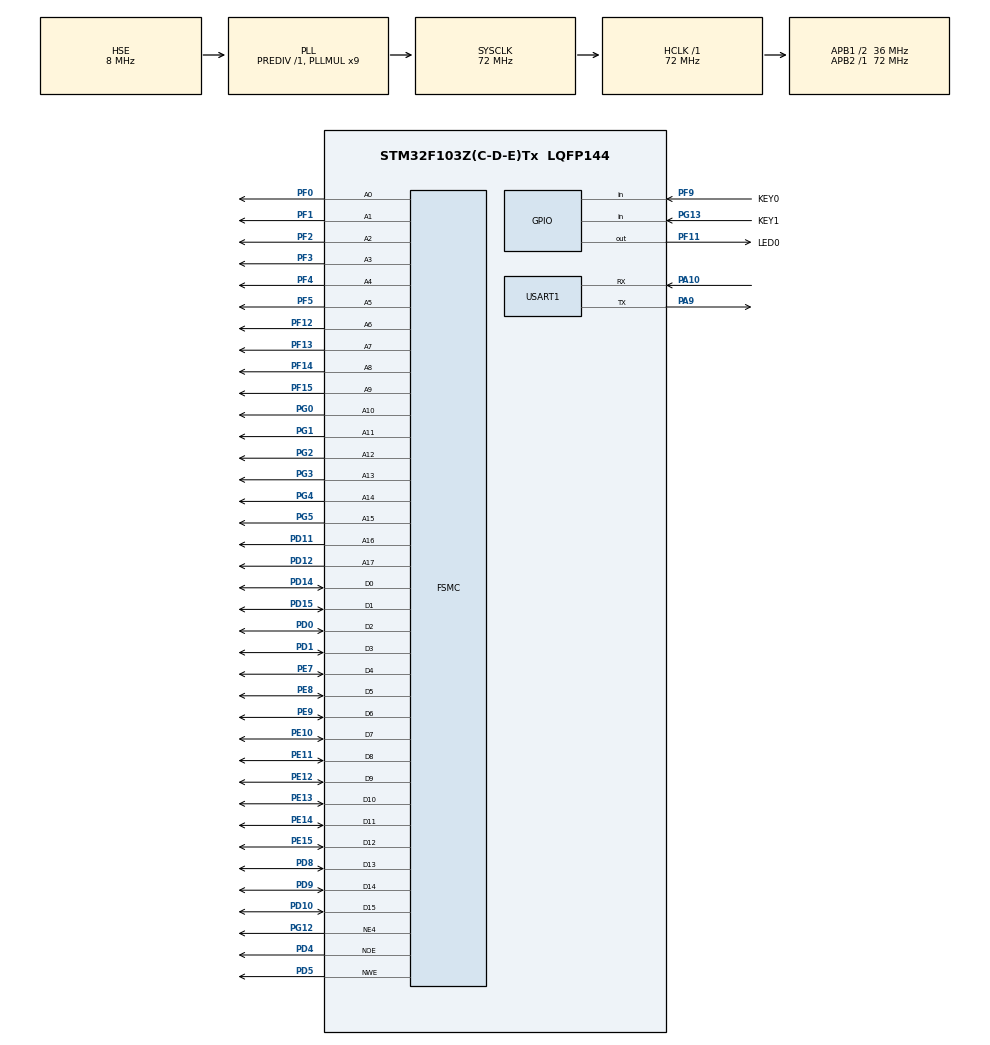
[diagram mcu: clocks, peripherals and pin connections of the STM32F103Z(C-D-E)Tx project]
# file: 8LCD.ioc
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FSMC.AddressSetupTime1=0
FSMC.DataSetupTime1=3
FSMC.WriteOperation1=FSMC_WRITE_OPERATION_ENABLE
Mcu.Family=STM32F1
Mcu.Name=STM32F103Z(C-D-E)Tx
Mcu.Package=LQFP144
NVIC.PriorityGroup=NVIC_PRIORITYGROUP_4
OSC_IN.Mode=HSE-External-Oscillator
OSC_IN.Signal=RCC_OSC_IN
OSC_OUT.Mode=HSE-External-Oscillator
OSC_OUT.Signal=RCC_OSC_OUT
PA10.Mode=Asynchronous
PA10.Signal=USART1_RX
PA13.Mode=Serial_Wire
PA13.Signal=SYS_JTMS-SWDIO
PA14.Mode=Serial_Wire
PA14.Signal=SYS_JTCK-SWCLK
PA9.Mode=Asynchronous
PA9.Signal=USART1_TX
PC14-OSC32_IN.Mode=LSE-External-Oscillator
PC14-OSC32_IN.Signal=RCC_OSC32_IN
PC15-OSC32_OUT.Mode=LSE-External-Oscillator
PC15-OSC32_OUT.Signal=RCC_OSC32_OUT
PD0.Signal=FSMC_D2_DA2
PD1.Signal=FSMC_D3_DA3
PD10.Signal=FSMC_D15_DA15
PD11.Signal=FSMC_A16_CLE
PD12.Signal=FSMC_A17_ALE
PD14.Signal=FSMC_D0_DA0
PD15.Signal=FSMC_D1_DA1
PD4.Signal=FSMC_NOE
PD5.Signal=FSMC_NWE
PD8.Signal=FSMC_D13_DA13
PD9.Signal=FSMC_D14_DA14
PE10.Signal=FSMC_D7_DA7
PE11.Signal=FSMC_D8_DA8
PE12.Signal=FSMC_D9_DA9
PE13.Signal=FSMC_D10_DA10
PE14.Signal=FSMC_D11_DA11
PE15.Signal=FSMC_D12_DA12
PE7.Signal=FSMC_D4_DA4
PE8.Signal=FSMC_D5_DA5
PE9.Signal=FSMC_D6_DA6
PF0.Signal=FSMC_A0
PF1.Signal=FSMC_A1
PF11.GPIO_Label=LED0
PF11.Signal=GPIO_Output
PF12.Signal=FSMC_A6
PF13.Signal=FSMC_A7
PF14.Signal=FSMC_A8
PF15.Signal=FSMC_A9
PF2.Signal=FSMC_A2
PF3.Signal=FSMC_A3
PF4.Signal=FSMC_A4
PF5.Signal=FSMC_A5
PF9.GPIO_Label=KEY0
PF9.GPIO_PuPd=GPIO_PULLUP
PF9.Signal=GPIO_Input
PG0.Signal=FSMC_A10
PG1.Signal=FSMC_A11
PG12.Mode=NorPsramChipSelect4_1
PG12.Signal=FSMC_NE4
PG13.GPIO_Label=KEY1
PG13.GPIO_PuPd=GPIO_PULLUP
PG13.Signal=GPIO_Input
PG2.Signal=FSMC_A12
PG3.Signal=FSMC_A13
PG4.Signal=FSMC_A14
PG5.Signal=FSMC_A15
ProjectManager.HeapSize=0x200
ProjectManager.StackSize=0x400
ProjectManager.TargetToolchain=MDK-ARM V5.27
RCC.AHBFreq_Value=72000000
RCC.APB1CLKDivider=RCC_HCLK_DIV2
RCC.APB1Freq_Value=36000000
RCC.APB1TimFreq_Value=72000000
RCC.APB2Freq_Value=72000000
RCC.APB2TimFreq_Value=72000000
RCC.HCLKFreq_Value=72000000
RCC.PLLMUL=RCC_PLL_MUL9
RCC.PLLSourceVirtual=RCC_PLLSOURCE_HSE
RCC.SYSCLKFreq_VALUE=72000000
RCC.SYSCLKSource=RCC_SYSCLKSOURCE_PLLCLK
RCC.USBFreq_Value=72000000
SH.FSMC_A0.0=FSMC_A0,18b-a1
SH.FSMC_A1.0=FSMC_A1,18b-a1
SH.FSMC_A10.0=FSMC_A10,18b-a1
SH.FSMC_A11.0=FSMC_A11,18b-a1
SH.FSMC_A12.0=FSMC_A12,18b-a1
SH.FSMC_A13.0=FSMC_A13,18b-a1
SH.FSMC_A14.0=FSMC_A14,18b-a1
SH.FSMC_A15.0=FSMC_A15,18b-a1
SH.FSMC_A16_CLE.0=FSMC_A16,18b-a1
SH.FSMC_A17_ALE.0=FSMC_A17,18b-a1
SH.FSMC_A2.0=FSMC_A2,18b-a1
SH.FSMC_A3.0=FSMC_A3,18b-a1
SH.FSMC_A4.0=FSMC_A4,18b-a1
SH.FSMC_A5.0=FSMC_A5,18b-a1
SH.FSMC_A6.0=FSMC_A6,18b-a1
SH.FSMC_A7.0=FSMC_A7,18b-a1
SH.FSMC_A8.0=FSMC_A8,18b-a1
SH.FSMC_A9.0=FSMC_A9,18b-a1
SH.FSMC_D0_DA0.0=FSMC_D0,16b-d1
SH.FSMC_D10_DA10.0=FSMC_D10,16b-d1
SH.FSMC_D11_DA11.0=FSMC_D11,16b-d1
SH.FSMC_D12_DA12.0=FSMC_D12,16b-d1
SH.FSMC_D13_DA13.0=FSMC_D13,16b-d1
SH.FSMC_D14_DA14.0=FSMC_D14,16b-d1
SH.FSMC_D15_DA15.0=FSMC_D15,16b-d1
SH.FSMC_D1_DA1.0=FSMC_D1,16b-d1
SH.FSMC_D2_DA2.0=FSMC_D2,16b-d1
SH.FSMC_D3_DA3.0=FSMC_D3,16b-d1
SH.FSMC_D4_DA4.0=FSMC_D4,16b-d1
SH.FSMC_D5_DA5.0=FSMC_D5,16b-d1
SH.FSMC_D6_DA6.0=FSMC_D6,16b-d1
SH.FSMC_D7_DA7.0=FSMC_D7,16b-d1
SH.FSMC_D8_DA8.0=FSMC_D8,16b-d1
SH.FSMC_D9_DA9.0=FSMC_D9,16b-d1
SH.FSMC_NOE.0=FSMC_NOE,Sram1
SH.FSMC_NWE.0=FSMC_NWE,Sram1
USART1.VirtualMode=VM_ASYNC
board=custom

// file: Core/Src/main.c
/* USER CODE BEGIN Header */
/**
  ******************************************************************************
  * @file           : main.c
  * @brief          : Main program body
  ******************************************************************************
  * @attention
  *
  * <h2><center>&copy; Copyright (c) 2021 STMicroelectronics.
  * All rights reserved.</center></h2>
  *
  * This software component is licensed by ST under BSD 3-Clause license,
  * the "License"; You may not use this file except in compliance with the
  * License. You may obtain a copy of the License at:
  *                        opensource.org/licenses/BSD-3-Clause
  *
  ******************************************************************************
  */
/* USER CODE END Header */
#include "main.h"
#include "usart.h"
#include "gpio.h"
#include "fsmc.h"

/* USER CODE BEGIN Includes */
#include "BSP_Graphics.h"
#include "BSP_TFTLCD.h"
/* USER CODE END Includes */

void SystemClock_Config(void);

int main(void)
{

  /* MCU Configuration--------------------------------------------------------*/

  /* Reset of all peripherals, Initializes the Flash interface and the Systick. */
  HAL_Init();

  /* Configure the system clock */
  SystemClock_Config();

  /* Initialize all configured peripherals */
  MX_GPIO_Init();
  MX_USART1_UART_Init();
  MX_FSMC_Init();

  /* USER CODE BEGIN 2 */
	BSP_TFTLCD_Init();
	//LcdClear(RED);
	LcdPrintHorz(0,240,800,BLACK);
	LcdPrintVert(400,0,480,BLACK);

	LcdFillRec(450,60,550,180,0,BLACK);
	LcdFillRec(650,60,750,180,1,BLACK);
	LcdPrintHorzZuHe(0,240,200,BLACK);
	LcdPrintStr("Clear",400,240,BLACK,WHITE,0);
	LcdPrintBIAS(400,480,800,240,BLACK);
  /* USER CODE END 2 */

  /* Infinite loop */
  while (1)
  {

  }
}

void SystemClock_Config(void)
{
  RCC_OscInitTypeDef RCC_OscInitStruct = {0};
  RCC_ClkInitTypeDef RCC_ClkInitStruct = {0};

  /** Initializes the RCC Oscillators according to the specified parameters
  * in the RCC_OscInitTypeDef structure.
  */
  RCC_OscInitStruct.OscillatorType = RCC_OSCILLATORTYPE_HSE;
  RCC_OscInitStruct.HSEState = RCC_HSE_ON;
  RCC_OscInitStruct.HSEPredivValue = RCC_HSE_PREDIV_DIV1;
  RCC_OscInitStruct.HSIState = RCC_HSI_ON;
  RCC_OscInitStruct.PLL.PLLState = RCC_PLL_ON;
  RCC_OscInitStruct.PLL.PLLSource = RCC_PLLSOURCE_HSE;
  RCC_OscInitStruct.PLL.PLLMUL = RCC_PLL_MUL9;
  if (HAL_RCC_OscConfig(&RCC_OscInitStruct) != HAL_OK)
  {
    Error_Handler();
  }
  /** Initializes the CPU, AHB and APB buses clocks
  */
  RCC_ClkInitStruct.ClockType = RCC_CLOCKTYPE_HCLK|RCC_CLOCKTYPE_SYSCLK
                              |RCC_CLOCKTYPE_PCLK1|RCC_CLOCKTYPE_PCLK2;
  RCC_ClkInitStruct.SYSCLKSource = RCC_SYSCLKSOURCE_PLLCLK;
  RCC_ClkInitStruct.AHBCLKDivider = RCC_SYSCLK_DIV1;
  RCC_ClkInitStruct.APB1CLKDivider = RCC_HCLK_DIV2;
  RCC_ClkInitStruct.APB2CLKDivider = RCC_HCLK_DIV1;

  if (HAL_RCC_ClockConfig(&RCC_ClkInitStruct, FLASH_LATENCY_2) != HAL_OK)
  {
    Error_Handler();
  }
}

void Error_Handler(void)
{
  __disable_irq();
  while (1)
  {
  }
}

/************************ (C) COPYRIGHT STMicroelectronics *****END OF FILE****/
